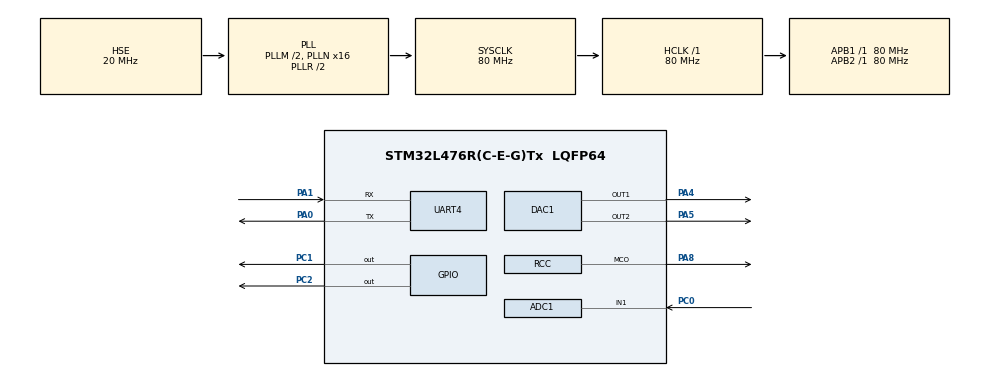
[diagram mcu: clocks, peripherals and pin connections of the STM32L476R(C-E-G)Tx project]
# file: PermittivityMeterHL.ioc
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ADC1.Channel-3\#ChannelRegularConversion=ADC_CHANNEL_9
ADC1.NbrOfConversionFlag=1
ADC1.OffsetNumber-3\#ChannelRegularConversion=ADC_OFFSET_NONE
ADC1.Rank-3\#ChannelRegularConversion=1
ADC1.SamplingTime-3\#ChannelRegularConversion=ADC_SAMPLETIME_2CYCLES_5
ADC1.master=1
DAC1.DAC_Channel-DAC_OUT2=DAC_CHANNEL_2
DAC1.DAC_HoldTime-DAC_OUT1=1000
DAC1.DAC_SampleAndHold-DAC_OUT1=DAC_SAMPLEANDHOLD_ENABLE
DAC1.DAC_SampleTime-DAC_OUT1=10
Mcu.Family=STM32L4
Mcu.Name=STM32L476R(C-E-G)Tx
Mcu.Package=LQFP64
NVIC.PriorityGroup=NVIC_PRIORITYGROUP_4
PA0.Mode=Asynchronous
PA0.Signal=UART4_TX
PA1.Mode=Asynchronous
PA1.Signal=UART4_RX
PA4.Signal=SharedAnalog_PA4
PA5.Signal=SharedAnalog_PA5
PA8.Mode=Clock-out
PA8.Signal=RCC_MCO
PC0.Signal=ADCx_IN1
PC1.Signal=GPIO_Output
PC2.Signal=GPIO_Output
PH0-OSC_IN\ (PH0).Mode=HSE-External-Oscillator
PH0-OSC_IN\ (PH0).Signal=RCC_OSC_IN
PH1-OSC_OUT\ (PH1).Mode=HSE-External-Oscillator
PH1-OSC_OUT\ (PH1).Signal=RCC_OSC_OUT
ProjectManager.HeapSize=0x200
ProjectManager.StackSize=0x400
ProjectManager.TargetToolchain=STM32CubeIDE
RCC.ADCFreq_Value=80000000
RCC.AHBFreq_Value=80000000
RCC.APB1Freq_Value=80000000
RCC.APB1TimFreq_Value=80000000
RCC.APB2Freq_Value=80000000
RCC.APB2TimFreq_Value=80000000
RCC.CortexFreq_Value=80000000
RCC.EnbaleCSS=true
RCC.HCLKFreq_Value=80000000
RCC.HSE_VALUE=20000000
RCC.HSI_VALUE=16000000
RCC.LSE_VALUE=32768
RCC.MSI_VALUE=4000000
RCC.PLLM=2
RCC.PLLN=16
RCC.PLLSAI1N=16
RCC.PLLSAI2N=10
RCC.PLLSAI2R=RCC_PLLR_DIV4
RCC.PLLSourceVirtual=RCC_PLLSOURCE_HSE
RCC.RCC_MCODiv=RCC_MCODIV_4
RCC.SYSCLKFreq_VALUE=80000000
RCC.SYSCLKSource=RCC_SYSCLKSOURCE_PLLCLK
RCC.UART4CLockSelection=RCC_UART4CLKSOURCE_SYSCLK
RCC.USART2CLockSelection=RCC_USART2CLKSOURCE_SYSCLK
RCC.USBFreq_Value=80000000
RCC.VCOOutputFreq_Value=160000000
SH.ADCx_IN1.0=ADC1_IN1,IN1-Single-Ended
SH.SharedAnalog_PA4.0=DAC1_OUT1,DAC_OUT1
SH.SharedAnalog_PA4.1=ADC1_IN9,IN9-Single-Ended
SH.SharedAnalog_PA5.0=DAC1_OUT2,DAC_OUT2
SH.SharedAnalog_PA5.1=ADC1_IN10,IN10-Single-Ended
SYS.PowerMode=PWR_SMPS_SUPPLY
VP_SYS_VS_LPOM.Mode=PowerOptimisation
VP_SYS_V_PVD_IN.Mode=Mode_PVD_Int
board=custom

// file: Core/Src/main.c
/* USER CODE BEGIN Header */
/**
  ******************************************************************************
  * @file           : main.c
  * @brief          : Main program body
  ******************************************************************************
  * @attention
  *
  * Copyright (c) 2025 STMicroelectronics.
  * All rights reserved.
  *
  * This software is licensed under terms that can be found in the LICENSE file
  * in the root directory of this software component.
  * If no LICENSE file comes with this software, it is provided AS-IS.
  *
  ******************************************************************************
  */
/* USER CODE END Header */
#include "main.h"

/* USER CODE BEGIN Includes */
#include "fsm_main.h"
/* USER CODE END Includes */

ADC_HandleTypeDef hadc1;

DAC_HandleTypeDef hdac1;

UART_HandleTypeDef huart4;

void SystemClock_Config(void);
static void MX_GPIO_Init(void);
static void MX_ADC1_Init(void);
static void MX_DAC1_Init(void);
static void MX_UART4_Init(void);

int main(void)
{

  /* MCU Configuration--------------------------------------------------------*/

  /* Reset of all peripherals, Initializes the Flash interface and the Systick. */
  HAL_Init();

  /* Configure the system clock */
  SystemClock_Config();

  /* Initialize all configured peripherals */
  MX_GPIO_Init();
  MX_ADC1_Init();
  MX_DAC1_Init();
  MX_UART4_Init();
  /* USER CODE BEGIN 2 */
  HAL_RCC_MCOConfig(RCC_MCO1, RCC_MCO1SOURCE_HSE, RCC_MCODIV_1);

  FSM_Init();
  /* USER CODE END 2 */

  /* Infinite loop */
  while (1)
  {

    /* USER CODE BEGIN 3 */
    FSM_RunOnce();
    HAL_Delay(1);
  }
  /* USER CODE END 3 */
}

void SystemClock_Config(void)
{
  RCC_OscInitTypeDef RCC_OscInitStruct = {0};
  RCC_ClkInitTypeDef RCC_ClkInitStruct = {0};

  /** Configure the main internal regulator output voltage
  */
  if (HAL_PWREx_ControlVoltageScaling(PWR_REGULATOR_VOLTAGE_SCALE1) != HAL_OK)
  {
    Error_Handler();
  }

  /** Initializes the RCC Oscillators according to the specified parameters
  * in the RCC_OscInitTypeDef structure.
  */
  RCC_OscInitStruct.OscillatorType = RCC_OSCILLATORTYPE_HSE;
  RCC_OscInitStruct.HSEState = RCC_HSE_ON;
  RCC_OscInitStruct.PLL.PLLState = RCC_PLL_ON;
  RCC_OscInitStruct.PLL.PLLSource = RCC_PLLSOURCE_HSE;
  RCC_OscInitStruct.PLL.PLLM = 2;
  RCC_OscInitStruct.PLL.PLLN = 16;
  RCC_OscInitStruct.PLL.PLLP = RCC_PLLP_DIV7;
  RCC_OscInitStruct.PLL.PLLQ = RCC_PLLQ_DIV2;
  RCC_OscInitStruct.PLL.PLLR = RCC_PLLR_DIV2;
  if (HAL_RCC_OscConfig(&RCC_OscInitStruct) != HAL_OK)
  {
    Error_Handler();
  }

  /** Initializes the CPU, AHB and APB buses clocks
  */
  RCC_ClkInitStruct.ClockType = RCC_CLOCKTYPE_HCLK|RCC_CLOCKTYPE_SYSCLK
                              |RCC_CLOCKTYPE_PCLK1|RCC_CLOCKTYPE_PCLK2;
  RCC_ClkInitStruct.SYSCLKSource = RCC_SYSCLKSOURCE_PLLCLK;
  RCC_ClkInitStruct.AHBCLKDivider = RCC_SYSCLK_DIV1;
  RCC_ClkInitStruct.APB1CLKDivider = RCC_HCLK_DIV1;
  RCC_ClkInitStruct.APB2CLKDivider = RCC_HCLK_DIV1;

  if (HAL_RCC_ClockConfig(&RCC_ClkInitStruct, FLASH_LATENCY_4) != HAL_OK)
  {
    Error_Handler();
  }
  HAL_RCC_MCOConfig(RCC_MCO1, RCC_MCO1SOURCE_SYSCLK, RCC_MCODIV_4);

  /** Enables the Clock Security System
  */
  HAL_RCC_EnableCSS();
}

static void MX_ADC1_Init(void)
{

  ADC_MultiModeTypeDef multimode = {0};
  ADC_ChannelConfTypeDef sConfig = {0};

  /** Common config
  */
  hadc1.Instance = ADC1;
  hadc1.Init.ClockPrescaler = ADC_CLOCK_ASYNC_DIV1;
  hadc1.Init.Resolution = ADC_RESOLUTION_12B;
  hadc1.Init.DataAlign = ADC_DATAALIGN_RIGHT;
  hadc1.Init.ScanConvMode = ADC_SCAN_DISABLE;
  hadc1.Init.EOCSelection = ADC_EOC_SINGLE_CONV;
  hadc1.Init.LowPowerAutoWait = DISABLE;
  hadc1.Init.ContinuousConvMode = DISABLE;
  hadc1.Init.NbrOfConversion = 1;
  hadc1.Init.DiscontinuousConvMode = DISABLE;
  hadc1.Init.ExternalTrigConv = ADC_SOFTWARE_START;
  hadc1.Init.ExternalTrigConvEdge = ADC_EXTERNALTRIGCONVEDGE_NONE;
  hadc1.Init.DMAContinuousRequests = DISABLE;
  hadc1.Init.Overrun = ADC_OVR_DATA_PRESERVED;
  hadc1.Init.OversamplingMode = DISABLE;
  if (HAL_ADC_Init(&hadc1) != HAL_OK)
  {
    Error_Handler();
  }

  /** Configure the ADC multi-mode
  */
  multimode.Mode = ADC_MODE_INDEPENDENT;
  if (HAL_ADCEx_MultiModeConfigChannel(&hadc1, &multimode) != HAL_OK)
  {
    Error_Handler();
  }

  /** Configure Regular Channel
  */
  sConfig.Channel = ADC_CHANNEL_9;
  sConfig.Rank = ADC_REGULAR_RANK_1;
  sConfig.SamplingTime = ADC_SAMPLETIME_2CYCLES_5;
  sConfig.SingleDiff = ADC_SINGLE_ENDED;
  sConfig.OffsetNumber = ADC_OFFSET_NONE;
  sConfig.Offset = 0;
  if (HAL_ADC_ConfigChannel(&hadc1, &sConfig) != HAL_OK)
  {
    Error_Handler();
  }

}

static void MX_DAC1_Init(void)
{

  DAC_ChannelConfTypeDef sConfig = {0};

  /** DAC Initialization
  */
  hdac1.Instance = DAC1;
  if (HAL_DAC_Init(&hdac1) != HAL_OK)
  {
    Error_Handler();
  }

  /** DAC channel OUT1 config
  */
  sConfig.DAC_SampleAndHold = DAC_SAMPLEANDHOLD_ENABLE;
  sConfig.DAC_Trigger = DAC_TRIGGER_NONE;
  sConfig.DAC_OutputBuffer = DAC_OUTPUTBUFFER_ENABLE;
  sConfig.DAC_ConnectOnChipPeripheral = DAC_CHIPCONNECT_DISABLE;
  sConfig.DAC_UserTrimming = DAC_TRIMMING_FACTORY;
  sConfig.DAC_SampleAndHoldConfig.DAC_SampleTime = 10;
  sConfig.DAC_SampleAndHoldConfig.DAC_HoldTime = 1000;
  sConfig.DAC_SampleAndHoldConfig.DAC_RefreshTime = 0;
  if (HAL_DAC_ConfigChannel(&hdac1, &sConfig, DAC_CHANNEL_1) != HAL_OK)
  {
    Error_Handler();
  }

  /** DAC channel OUT2 config
  */
  sConfig.DAC_SampleAndHold = DAC_SAMPLEANDHOLD_DISABLE;
  if (HAL_DAC_ConfigChannel(&hdac1, &sConfig, DAC_CHANNEL_2) != HAL_OK)
  {
    Error_Handler();
  }

}

static void MX_UART4_Init(void)
{

  huart4.Instance = UART4;
  huart4.Init.BaudRate = 115200;
  huart4.Init.WordLength = UART_WORDLENGTH_8B;
  huart4.Init.StopBits = UART_STOPBITS_1;
  huart4.Init.Parity = UART_PARITY_NONE;
  huart4.Init.Mode = UART_MODE_TX_RX;
  huart4.Init.HwFlowCtl = UART_HWCONTROL_NONE;
  huart4.Init.OverSampling = UART_OVERSAMPLING_16;
  huart4.Init.OneBitSampling = UART_ONE_BIT_SAMPLE_DISABLE;
  huart4.AdvancedInit.AdvFeatureInit = UART_ADVFEATURE_NO_INIT;
  if (HAL_UART_Init(&huart4) != HAL_OK)
  {
    Error_Handler();
  }

}

static void MX_GPIO_Init(void)
{
  GPIO_InitTypeDef GPIO_InitStruct = {0};

  /* GPIO Ports Clock Enable */
  __HAL_RCC_GPIOH_CLK_ENABLE();
  __HAL_RCC_GPIOC_CLK_ENABLE();
  __HAL_RCC_GPIOA_CLK_ENABLE();

  /*Configure GPIO pin Output Level */
  HAL_GPIO_WritePin(GPIOC, GPIO_PIN_1|GPIO_PIN_2, GPIO_PIN_RESET);

  /*Configure GPIO pins : PC1 PC2 */
  GPIO_InitStruct.Pin = GPIO_PIN_1|GPIO_PIN_2;
  GPIO_InitStruct.Mode = GPIO_MODE_OUTPUT_PP;
  GPIO_InitStruct.Pull = GPIO_NOPULL;
  GPIO_InitStruct.Speed = GPIO_SPEED_FREQ_LOW;
  HAL_GPIO_Init(GPIOC, &GPIO_InitStruct);

  /*Configure GPIO pin : PA8 */
  GPIO_InitStruct.Pin = GPIO_PIN_8;
  GPIO_InitStruct.Mode = GPIO_MODE_AF_PP;
  GPIO_InitStruct.Pull = GPIO_NOPULL;
  GPIO_InitStruct.Speed = GPIO_SPEED_FREQ_LOW;
  GPIO_InitStruct.Alternate = GPIO_AF0_MCO;
  HAL_GPIO_Init(GPIOA, &GPIO_InitStruct);

}

void Error_Handler(void)
{
  __disable_irq();
  while (1)
  {
  }
}
